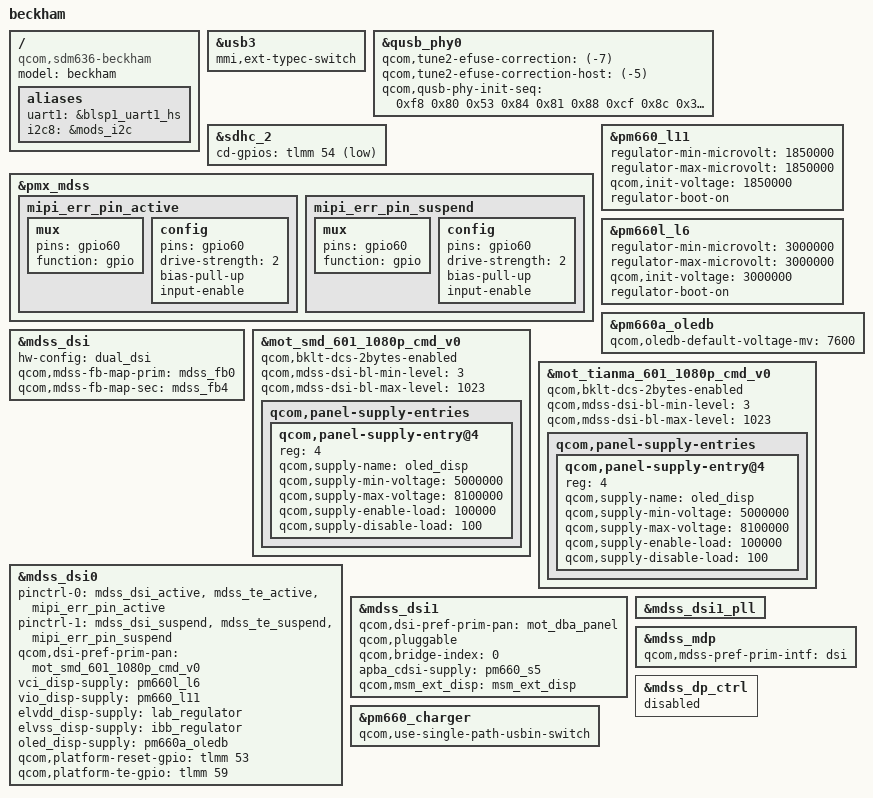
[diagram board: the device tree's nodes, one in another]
/* Copyright (c) 2016, Motorola Mobility Inc. All rights reserved.
 *
 * This program is free software; you can redistribute it and/or modify
 * it under the terms of the GNU General Public License version 2 and
 * only version 2 as published by the Free Software Foundation.
 *
 * This program is distributed in the hope that it will be useful,
 * but WITHOUT ANY WARRANTY; without even the implied warranty of
 * MERCHANTABILITY or FITNESS FOR A PARTICULAR PURPOSE.  See the
 * GNU General Public License for more details.
 */

//#include "sdm660-moto-common.dtsi"
#include "msm-pm660a.dtsi"
#include "sdm660-external-codec.dtsi"
#include "sdm660-beckham-pinctrl.dtsi"
#include "sdm660-beckham-audio.dtsi"
#include "dsi-panel-mot-smd-601-1080p-cmd.dtsi"
#include "dsi-panel-mot-tianma-601-1080p-cmd.dtsi"
#include "carrier-channel-ids.dtsi"

/ {
	model = "beckham";
	compatible = "qcom,sdm636-beckham", "qcom,sdm636-moto",
			"qcom,sdm636";
	aliases {
		/delete-property/ i2c3;
		uart1 = &blsp1_uart1_hs;
		i2c8 = &mods_i2c;
	};
};

&usb3{
	/delete-property/ pinctrl-names;
	/delete-property/ pinctrl-0;
};

&qusb_phy0{
	qcom,tune2-efuse-correction = <(-7)>;
	qcom,tune2-efuse-correction-host = <(-5)>;
	qcom,qusb-phy-init-seq = <0xf8 0x80
				0x53 0x84
				0x81 0x88
				0xcf 0x8c
				0x30 0x08
				0x79 0x0c
				0x21 0x10
				0x14 0x9c
				0x9f 0x1c
				0x00 0x18>;
};

&sdhc_2 {
	cd-gpios = <&tlmm 54 0x1>;
};

&pmx_mdss {
	mipi_err_pin_active: mipi_err_pin_active {
		mux {
			pins = "gpio60";
			function = "gpio";
		};

		config {
			pins = "gpio60";
			drive-strength = <2>; /* 2 mA */
			bias-pull-up; /* pull up */
			input-enable;
		};
	};

	mipi_err_pin_suspend: mipi_err_pin_suspend {
		mux {
			pins = "gpio60";
			function = "gpio";
		};

		config {
			pins = "gpio60";
			drive-strength = <2>; /* 2 mA */
			bias-pull-up; /* pull up */
			input-enable;
		};
	};
};

&pm660_l11 {
	regulator-min-microvolt = <1850000>;
	regulator-max-microvolt = <1850000>;
	qcom,init-voltage = <1850000>;
	regulator-boot-on;
};

&pm660l_l6 {
	regulator-min-microvolt = <3000000>;
	regulator-max-microvolt = <3000000>;
	qcom,init-voltage = <3000000>;
	regulator-boot-on;
};

&pm660a_oledb {
	qcom,oledb-default-voltage-mv = <7600>;
};

&mdss_dsi {
	hw-config = "dual_dsi";

	qcom,mdss-fb-map-prim = <&mdss_fb0>;
	qcom,mdss-fb-map-sec = <&mdss_fb4>;
};

&mot_smd_601_1080p_cmd_v0 {
	qcom,bklt-dcs-2bytes-enabled;
	qcom,mdss-dsi-bl-min-level = <3>;
	qcom,mdss-dsi-bl-max-level = <1023>;

	qcom,panel-supply-entries {
			qcom,panel-supply-entry@4 {
				reg = <4>;
				qcom,supply-name = "oled_disp";
				qcom,supply-min-voltage = <5000000>;
				qcom,supply-max-voltage = <8100000>;
				qcom,supply-enable-load = <100000>;
				qcom,supply-disable-load = <100>;
			};
	};
};

&mot_tianma_601_1080p_cmd_v0 {
	qcom,bklt-dcs-2bytes-enabled;
	qcom,mdss-dsi-bl-min-level = <3>;
	qcom,mdss-dsi-bl-max-level = <1023>;

	qcom,panel-supply-entries {
			qcom,panel-supply-entry@4 {
				reg = <4>;
				qcom,supply-name = "oled_disp";
				qcom,supply-min-voltage = <5000000>;
				qcom,supply-max-voltage = <8100000>;
				qcom,supply-enable-load = <100000>;
				qcom,supply-disable-load = <100>;
			};
	};
};

&mdss_dsi0 {
	pinctrl-names = "mdss_default", "mdss_sleep";
	pinctrl-0 = <&mdss_dsi_active &mdss_te_active &mipi_err_pin_active>;
	pinctrl-1 = <&mdss_dsi_suspend &mdss_te_suspend &mipi_err_pin_suspend>;

	qcom,dsi-pref-prim-pan = <&mot_smd_601_1080p_cmd_v0>;
	vci_disp-supply = <&pm660l_l6>;
	vio_disp-supply = <&pm660_l11>;
	elvdd_disp-supply = <&lab_regulator>;
	elvss_disp-supply = <&ibb_regulator>;
	oled_disp-supply = <&pm660a_oledb>;
	qcom,platform-reset-gpio = <&tlmm 53 0>;
	qcom,platform-te-gpio = <&tlmm 59 0>;

	/delete-property/  qcom,mdss-fb-map;
};

&mdss_dsi1 {
	status = "okay";
	qcom,dsi-pref-prim-pan = <&mot_dba_panel>;
	qcom,pluggable;
	qcom,bridge-index = <0>;
	apba_cdsi-supply = <&pm660_s5>;
	qcom,msm_ext_disp = <&msm_ext_disp>;

	/delete-property/  qcom,mdss-fb-map;
};

&mdss_dsi1_pll {
	/delete-property/ qcom,dsi-pll-ssc-en;
	/delete-property/ qcom,dsi-pll-ssc-mode;
};

&mdss_mdp {
	qcom,mdss-pref-prim-intf = "dsi";
};

&mdss_dp_ctrl {
	status = "disabled";
};

&usb3{
	mmi,ext-typec-switch;
};

&pm660_charger {
	qcom,use-single-path-usbin-switch;
};
